# f28p551x_access_protection_regs register map
Vendor: Texas Instruments
Peripheral module from a debugger description file (folder C2000).
Address unit: 16 bits
Registers are 32-bit, read-only, no defined reset value unless marked. A register's access mark holds for its fields unless they carry their own. Offsets are as the file gives them; lines under a group give offsets from that group; [hi:lo] are bit positions; {n}, {i} and the like mark numbered series; 'fields as' and 'values as' point back to an identical list; <NAME> marks a mode.

## ACCESS_PROTECTION_REGS — ACCESS PROTECTION Registers
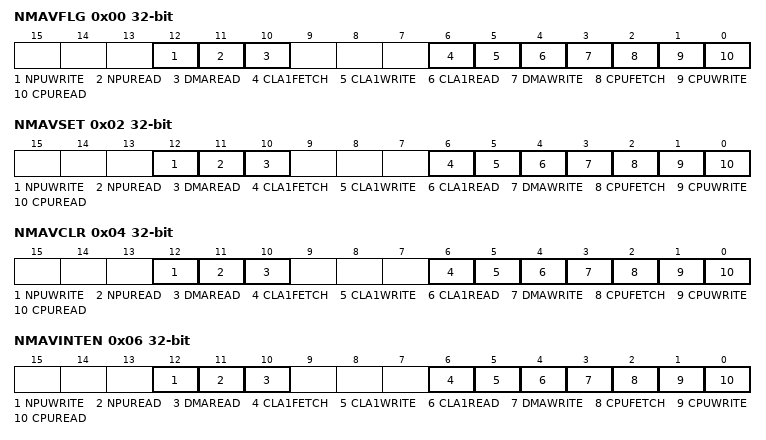
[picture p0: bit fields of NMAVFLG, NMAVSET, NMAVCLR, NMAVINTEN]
0x00 NMAVFLG — Non-Controller Access Violation Flag Register
  [12] NPUWRITE — Non Controller NPU Write Violation Flag
  [11] NPUREAD — Non Controller NPU Read Access Violation Flag
  [10] DMAREAD — Non Controller DMA Read Access Violation Flag
  [6] CLA1FETCH — Non Controller CLA1 Fetch Access Violation Flag
  [5] CLA1WRITE — Non Controller CLA1 Write Access Violation Flag
  [4] CLA1READ — Non Controller CLA1 Read Access Violation Flag
  [3] DMAWRITE — Non Controller DMA Write Access Violation Flag
  [2] CPUFETCH — Non Controller CPU Fetch Access Violation Flag
  [1] CPUWRITE — Non Controller CPU Write Access Violation Flag
  [0] CPUREAD — Non Controller CPU Read Access Violation Flag
0x02 NMAVSET rw — Non-Controller Access Violation Flag Set Register
  [12] NPUWRITE — Non Controller NPU Write Access Violation Flag Set
  [11] NPUREAD — Non Controller NPU Read Access Violation Flag Set
  [10] DMAREAD — Non Controller DMA Read Access Violation Flag Set
  [6] CLA1FETCH — Non Controller CLA1 Fetch Access Violation Flag Set
  [5] CLA1WRITE — Non Controller CLA1 Write Access Violation Flag Set
  [4] CLA1READ — Non Controller CLA1 Read Access Violation Flag Set
  [3] DMAWRITE — Non Controller DMA Write Access Violation Flag Set
  [2] CPUFETCH — Non Controller CPU Fetch Access Violation Flag Set
  [1] CPUWRITE — Non Controller CPU Write Access Violation Flag Set
  [0] CPUREAD — Non Controller CPU Read Access Violation Flag Set
0x04 NMAVCLR rw — Non-Controller Access Violation Flag Clear Register
  [12] NPUWRITE — Non Controller NPU Write Access Violation Flag Clear
  [11] NPUREAD — Non Controller NPU Read Access Violation Flag Clear
  [10] DMAREAD — Non Controller DMA Read Access Violation Flag Clear
  [6] CLA1FETCH — Non Controller CLA1 Fetch Access Violation Flag Clear
  [5] CLA1WRITE — Non Controller CLA1 Write Access Violation Flag Clear
  [4] CLA1READ — Non Controller CLA1 Read Access Violation Flag Clear
  [3] DMAWRITE — Non Controller DMA Write Access Violation Flag Clear
  [2] CPUFETCH — Non Controller CPU Fetch Access Violation Flag Clear
  [1] CPUWRITE — Non Controller CPU Write Access Violation Flag Clear
  [0] CPUREAD — Non Controller CPU Read Access Violation Flag Clear
0x06 NMAVINTEN rw — Non-Controller Access Violation Interrupt Enable Register
  [12] NPUWRITE — Non Controller NPU Write Violation Interrupt Enable
  [11] NPUREAD — Non Controller NPU Read Access Violation Interrupt Enable
  [10] DMAREAD — Non Controller DMA Read Access Violation Interrupt Enable
  [6] CLA1FETCH — Non Controller CLA1 Fetch Access Violation Interrupt Enable
  [5] CLA1WRITE — Non Controller CLA1 Write Access Violation Interrupt Enable
  [4] CLA1READ — Non Controller CLA1 Read Access Violation Interrupt Enable
  [3] DMAWRITE — Non Controller DMA Write Access Violation Interrupt Enable
  [2] CPUFETCH — Non Controller CPU Fetch Access Violation Interrupt Enable
  [1] CPUWRITE — Non Controller CPU Write Access Violation Interrupt Enable
  [0] CPUREAD — Non Controller CPU Read Access Violation Interrupt Enable
0x08 NMCPURDAVADDR — Non-Controller CPU Read Access Violation Address
  [31:0] NMCPURDAVADDR — Non Controller CPU read access violation address register.
0x0A NMCPUWRAVADDR — Non-Controller CPU Write Access Violation Address
  [31:0] NMCPUWRAVADDR — Non Controller CPU write access violation address register.
0x0C NMCPUFAVADDR — Non-Controller CPU Fetch Access Violation Address
  [31:0] NMCPUFAVADDR — Non Controller CPU fetch access violation address register.
0x0E NMDMAWRAVADDR — Non-Controller DMA Write Access Violation Address
  [31:0] NMDMAWRAVADDR — Non Controller DMA write access violation address register.
0x10 NMCLA1RDAVADDR — Non-Controller CLA1 Read Access Violation Address
  [31:0] NMCLA1RDAVADDR — Non Controller CLA1 read access violation address register.
0x12 NMCLA1WRAVADDR — Non-Controller CLA1 Write Access Violation Address
  [31:0] NMCLA1WRAVADDR — Non Controller CLA1 write violation address register.
0x14 NMCLA1FAVADDR — Non-Controller CLA1 Fetch Access Violation Address
  [31:0] NMCLA1FAVADDR — Non Controller CLA1 fetch violation address register.
0x1C NMDMARDAVADDR — Non-Controller DMA Read Access Violation Address
  [31:0] NMDMARDAVADDR — Non Controller DMA read access violation address register.
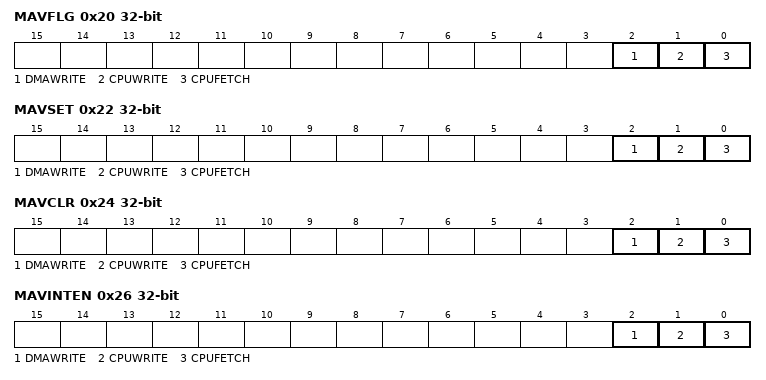
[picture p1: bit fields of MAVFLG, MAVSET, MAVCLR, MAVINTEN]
0x20 MAVFLG — Controller Access Violation Flag Register
  [2] DMAWRITE — Controller DMA Write Access Violation Flag
  [1] CPUWRITE — Controller CPU Write Access Violation Flag
  [0] CPUFETCH — Controller CPU Fetch Access Violation Flag
0x22 MAVSET rw — Controller Access Violation Flag Set Register
  [2] DMAWRITE — Controller DMA Write Access Violation Flag Set
  [1] CPUWRITE — Controller CPU Write Access Violation Flag Set
  [0] CPUFETCH — Controller CPU Fetch Access Violation Flag Set
0x24 MAVCLR rw — Controller Access Violation Flag Clear Register
  [2] DMAWRITE — Controller DMA Write Access Violation Flag Clear
  [1] CPUWRITE — Controller CPU Write Access Violation Flag Clear
  [0] CPUFETCH — Controller CPU Fetch Access Violation Flag Clear
0x26 MAVINTEN rw — Controller Access Violation Interrupt Enable Register
  [2] DMAWRITE — Controller DMA Write Access Violation Interrupt Enable
  [1] CPUWRITE — Controller CPU Write Access Violation Interrupt Enable
  [0] CPUFETCH — Controller CPU Fetch Access Violation Interrupt Enable
0x28 MCPUFAVADDR — Controller CPU Fetch Access Violation Address
  [31:0] MCPUFAVADDR — Controller CPU fetch access violation address register.
0x2A MCPUWRAVADDR — Controller CPU Write Access Violation Address
  [31:0] MCPUWRAVADDR — Controller CPU write access violation address register.
0x2C MDMAWRAVADDR — Controller DMA Write Access Violation Address
  [31:0] MDMAWRAVADDR — Controller DMA write access violation address register.
0x3A NMNPURDAVADDR — Non-Controller NPU Read Access Violation Address
  [31:0] NMNPURDAVADDR — Non Controller NPU read violation address register.
0x3C NMNPUWRAVADDR — Non-Controller NPU Write Access Violation Address
  [31:0] NMNPUWRAVADDR — Non Controller NPU write violation address register.
